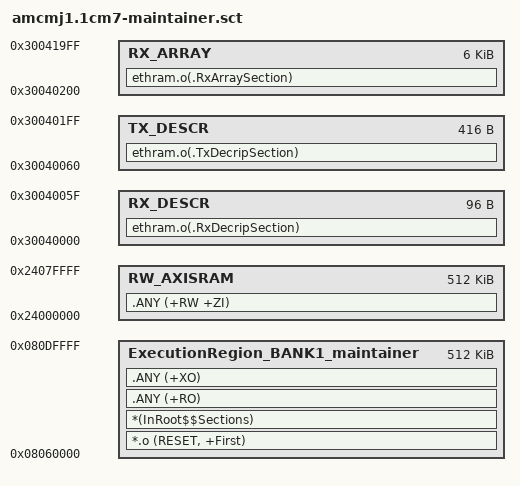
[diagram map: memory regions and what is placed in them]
; amcmj1-maintainer running on cm7. it uses following FLASH and RAM resources:
; 
; - FLASH: 1st bank @ 0x08060000 for a size of 512k
; 
; - RAM: AXI SRAM @ 0x24000000 for a size of 512k
; 
; the memory for IPC is @ 0x1003FFC0, on the top 64 bytes of SRAM1-SRAM2 used by the CM4

LoadRegion_BANK1_maintainer 0x08060000 0x00080000  {    

  ; execution region is in flash
  ExecutionRegion_BANK1_maintainer 0x08060000 0x00080000  {  ; load address = execution address
   *.o (RESET, +First)
   *(InRoot$$Sections)
   .ANY (+RO)
   .ANY (+XO)
  }
  
  ; eth mapping. comment it out if ethram.o is not linked
  RX_DESCR	0x30040000 0x00000060 {
  	ethram.o(.RxDecripSection)
  }
  TX_DESCR	0x30040060 0x000001A0 {
  	ethram.o(.TxDecripSection)
  }
  RX_ARRAY 	0x30040200 0x00001800 {
  	ethram.o(.RxArraySection)
  }
  
  ; ram: AXI SRAM @ 0x24000000
  RW_AXISRAM 0x24000000 0x00080000  {
   .ANY (+RW +ZI)
  }
  
}
